# AS32x601 register map
File version: 1.0
CPU: RISC-V, little endian
Registers are 32-bit, read-write, reset 0x0 unless marked. A register's access mark holds for its fields unless they carry their own. Offsets are from the block's base; [hi:lo] are bit positions; lines under a group give offsets from that group; {n}, {i} and the like mark numbered series.

## CANFD0 — CAN FD Controller 0
Base 0x41010000
Same registers: CANFD1 0x41020000, CANFD2 0x42010000, CANFD3 0x42020000
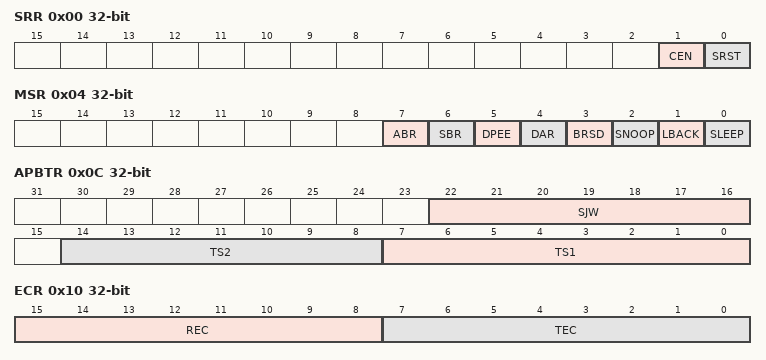
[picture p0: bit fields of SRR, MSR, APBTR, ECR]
0x00 SRR — Software Reset Register
  [1] CEN — CAN Enable
  [0] SRST — Reset
0x04 MSR — Mode Select Register
  [7] ABR — Auto Bus-Off Recovery Request
  [6] SBR — Start Bus-Off Recovery Request
  [5] DPEE — Disable Protocol Exception Event Detection/Generation
  [4] DAR — Disable Auto-Retransmission
  [3] BRSD — CAN FD Bit Rate Switch Disable Override
  [2] SNOOP — SNOOP Mode Select/Request
  [1] LBACK — Loopback Mode Select/Request
  [0] SLEEP — Sleep Mode Select/Request
0x08 APBRPR — Arbitration Phase (Nominal) Baud Rate Prescaler Register
  [7:0] BRP — BRP[7:0] bits (Arbitration Phase Baud Rate Prescaler)
0x0C APBTR — Arbitration Phase (Nominal) Bit Timing Register
  [22:16] SJW — SJW[6:0] bits (Synchronization Jump Width)
  [14:8] TS2 — TS2[6:0] bits (Time Segment 2)
  [7:0] TS1 — TS1[7:0] bits (Time Segment 1)
0x10 ECR ro — Error Count Register
  [15:8] REC — REC[7:0] bits (Receive Error Count)
  [7:0] TEC — TEC[7:0] bits (Transmit Error Count)
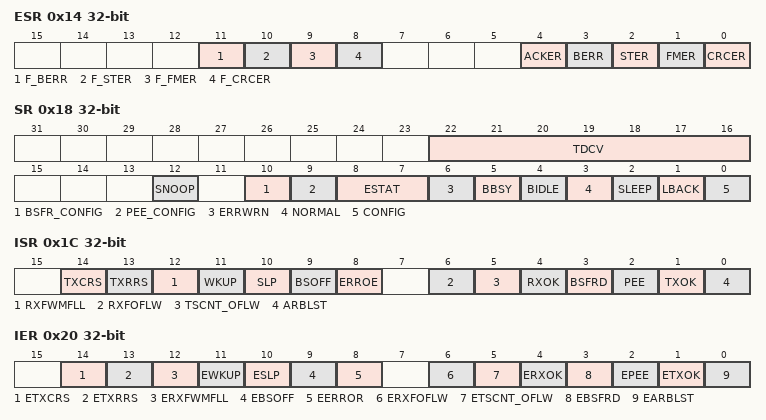
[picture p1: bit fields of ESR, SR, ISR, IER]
0x14 ESR — Error Status Register
  [11] F_BERR — Bit Error in CAN FD Data Phase
  [10] F_STER — Stuff Error in CAN FD Data Phase
  [9] F_FMER — Form Error in CAN FD Data Phase
  [8] F_CRCER — CRC Error in CAN FD Data Phase
  [4] ACKER — ACK Error
  [3] BERR — Bit Error
  [2] STER — Stuff Error
  [1] FMER — Form Error
  [0] CRCER — CRC Error
0x18 SR ro — Status Register
  [22:16] TDCV — TDCV[6:0] bits (Transmitter Delay Compensation Value)
  [12] SNOOP — Snoop Mode
  [10] BSFR_CONFIG — Bus-Off Recovery Mode Indicator
  [9] PEE_CONFIG — PEE Mode Indicator
  [8:7] ESTAT — ESTAT[1:0] bits (Error Status)
  [6] ERRWRN — Error Warning
  [5] BBSY — Indicates the CAN bus status
  [4] BIDLE — Bus Idle
  [3] NORMAL — Normal Mode
  [2] SLEEP — Sleep Mode
  [1] LBACK — Loopback Mode
  [0] CONFIG — Configuration Mode Indicator
0x1C ISR ro — Interrupt Status Register
  [14] TXCRS — TX Cancellation Request Served Interrupt
  [13] TXRRS — TX Buffer Ready Request Served Interrupt
  [12] RXFWMFLL — RX FIFO-0 Full Level Interrupt (sequential/FIFO mode)
  [11] WKUP — Wake-Up Interrupt
  [10] SLP — Sleep Interrupt
  [9] BSOFF — Bus-Off Interrupt
  [8] ERROE — Error Interrupt
  [6] RXFOFLW — RX FIFO-0 Overflow Interrupt
  [5] TSCNT_OFLW — Timestamp Counter Overflow Interrupt
  [4] RXOK — New Message Received Interrupt
  [3] BSFRD — Bus-Off Recovery Done Interrupt
  [2] PEE — Protocol Exception Event Interrupt
  [1] TXOK — Transmission Successful Interrupt
  [0] ARBLST — Arbitration Lost Interrupt
0x20 IER — Interrupt Enable Register
  [14] ETXCRS — TX Cancellation Request Served Interrupt Enable
  [13] ETXRRS — TX Buffer Ready Request Served Interrupt Enable
  [12] ERXFWMFLL — RX FIFO-0 Full Level Interrupt Enable (sequential/FIFO mode)
  [11] EWKUP — Wake-Up Interrupt Enable
  [10] ESLP — Sleep Interrupt Enable
  [9] EBSOFF — Bus-Off Interrupt Enable
  [8] EERROR — Error Interrupt Enable
  [6] ERXFOFLW — RX FIFO-0 Overflow Interrupt Enable
  [5] ETSCNT_OFLW — Timestamp Counter Overflow Interrupt Enable
  [4] ERXOK — New Message Received Interrupt Enable
  [3] EBSFRD — Bus-Off Recovery Done Interrupt Enable
  [2] EPEE — Protocol Exception Event Interrupt Enable
  [1] ETXOK — Transmission Successful Interrupt Enable
  [0] EARBLST — Arbitration Lost Interrupt Enable
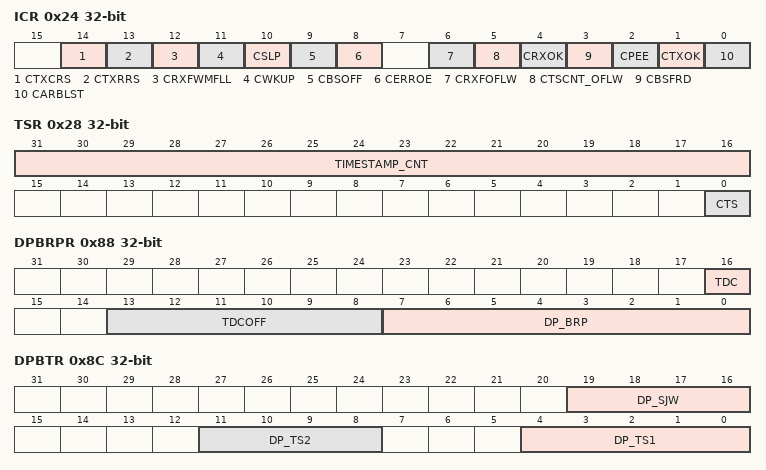
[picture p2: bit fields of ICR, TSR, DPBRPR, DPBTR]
0x24 ICR wo — Interrupt Clear Register
  [14] CTXCRS — Clears TX Cancellation Request Served Interrupt
  [13] CTXRRS — Clears TX Buffer Ready Request Served Interrupt
  [12] CRXFWMFLL — Clears RX FIFO-0 Full Level Interrupt(sequential/FIFO mode)
  [11] CWKUP — Clears Wake-Up interrupt
  [10] CSLP — Clears Sleep interrupt
  [9] CBSOFF — Clears Bus-Off interrupt
  [8] CERROE — Clears Error interrupt
  [6] CRXFOFLW — Clears RX FIFO-0 Overflow interrupt
  [5] CTSCNT_OFLW — Clears Timestamp Counter Overflow Interrupt
  [4] CRXOK — Clears New Message Received interrupt
  [3] CBSFRD — Clears Bus-Off Recovery Done interrupt
  [2] CPEE — Clears Protocol Exception Event interrupt
  [1] CTXOK — Clears Transmission Successful interrupt
  [0] CARBLST — Clears Arbitration Lost interrupt
0x28 TSR — Timestamp Register
  [31:16] TIMESTAMP_CNT — TIMESTAMP_CNT[15:0] bits (Timestamp Counter Value)
  [0] CTS — Clear Timestamp Counter
0x88 DPBRPR — Data Phase Baud Rate Prescaler Register
  [16] TDC — Transmitter Delay Compensation (TDC) Enable
  [13:8] TDCOFF — TDCOFF[5:0] bits (Transmitter Delay Compensation Offset)
  [7:0] DP_BRP — DP_BRP[7:0] bits (Data Phase Baud Rate Prescaler)
0x8C DPBTR — Data Phase Bit Timing Register
  [19:16] DP_SJW — DP_SJW[3:0] bits (Data Phase Synchronization Jump Width)
  [11:8] DP_TS2 — DP_TS2[3:0] bits (Data Phase Time Segment 2)
  [4:0] DP_TS1 — DP_TS1[4:0] bits (Data Phase Time Segment 1)
0x90 TRR — TX Buffer Ready Request Register
  [31:0] RR — RR[31:0] bits (TX Buffer Ready Request)
0x94 ERRS — Interrupt Enable TX Buffer Ready Request Served/Cleared
  [31:0] ERRS — ERRS[31:0] bits (TX Buffer Ready Req Served/Cleared Interrupt Enable)
0x98 TCR — TX Buffer Cancel Request
  [31:0] CR — CR[31:0] bits (TX Buffer Cancel Request)
0x9C ECRS — Interrupt Enable TX Buffer Cancellation Served/Cleared
  [31:0] ECRS — ECRS[31:0] bits (TX Buffer Transmission Served/Cleared Interrupt Enable)
0xE0 AFR — Acceptance Filter (Control) Register
  [31:0] UAF — UAF[31:0] bits (Use Acceptance Filter Mask Pair)
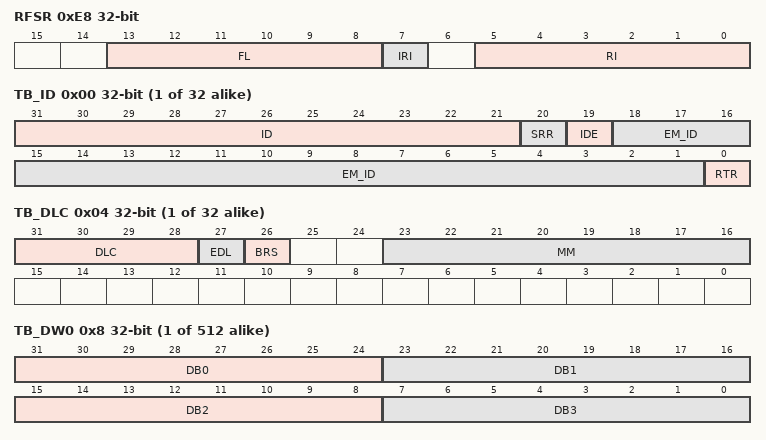
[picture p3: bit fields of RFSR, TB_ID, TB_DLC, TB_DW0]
0xE8 RFSR — RX FIFO Status Register
  [13:8] FL — FL[5:0] bits (RX FIFO Fill Level 0 to 64)
  [7] IRI — RX FIFO Increment Read Index by 1
  [5:0] RI — RI[5:0] bits (RX FIFO Read Index 0 to 63)
{0x100+0x48*i} TxMessage[{i}] (i=0..31) group — CAN FD TX Message Space Register Descriptions (32 pairs)
  0x00 TB_ID — TX Buffer ID Register
    [31:21] ID — ID[28:18] bits (Standard Message ID)
    [20] SRR — Substitute Remote Transmission Request
    [19] IDE — Identifier Extension
    [18:1] EM_ID — ID[17:0] bits (Extended Message ID)
    [0] RTR — Remote Transmission Request
  0x04 TB_DLC — TX Buffer DLC Register
    [31:28] DLC — DLC[3:0] bits (Data Length Code)
    [27] EDL — Extended Data Length/FD Frame Format
    [26] BRS — Bit Rate Switch
    [23:16] MM — MM[7:0] bits (Written by CPU during TX Buffer configuration)
  {0x8+4j} TB_DW{j} (j=0..15) — TX Buffer Data Word {j} Register
    [31-8n:24-8n] DB{n} (n=0..3) — Data bytes[7:0] bits {n} (Data Byte)
{0xA00+8i} RxFiltering[{i}] (i=0..31) group — Acceptance Filter Registers (32 pairs)
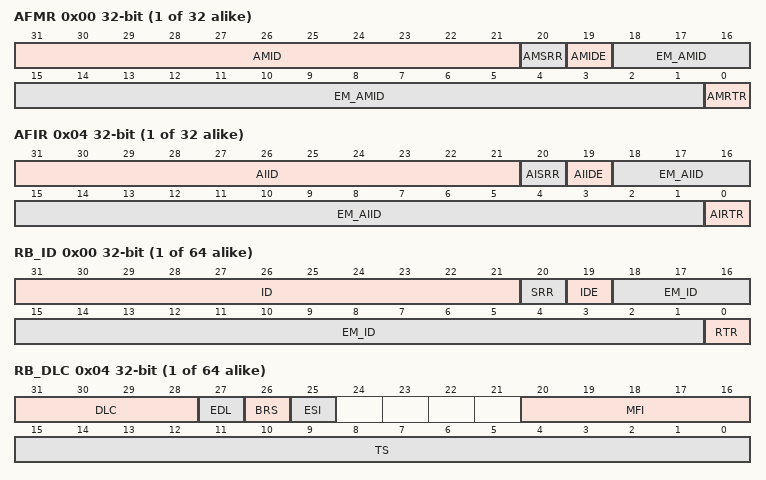
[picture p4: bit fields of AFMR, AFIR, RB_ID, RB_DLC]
  0x00 AFMR — Acceptance Filter Mask Register
    [31:21] AMID — Standard Message ID Mask
    [20] AMSRR — Substitute Remote Transmission Request Mask
    [19] AMIDE — Identifier Extension Mask
    [18:1] EM_AMID — Extended Message ID Mask
    [0] AMRTR — Remote Transmission Request Mask
  0x04 AFIR — Acceptance Filter ID Register
    [31:21] AIID — Standard Message ID
    [20] AISRR — Substitute Remote Transmission Request
    [19] AIIDE — Identifier Extension
    [18:1] EM_AIID — Extended Message ID
    [0] AIRTR — Remote Transmission Request
{0x2100+0x48*i} RxMessage[{i}] (i=0..63) group — CAN FD RX Message Space (Sequential/FIFO Buffers-RX FIFO) Register Descriptions
  0x00 RB_ID ro
    [31:21] ID — Standard Message ID
    [20] SRR — Substitute Remote Transmission Request
    [19] IDE — Identifier Extension
    [18:1] EM_ID — Extended Message ID
    [0] RTR — Remote Transmission Request
  0x04 RB_DLC ro
    [31:28] DLC — Data Length Code
    [27] EDL — Extended Data Length/FD Frame Format
    [26] BRS — Bit Rate Switch
    [25] ESI — Error State Indicator
    [20:16] MFI — Matched Filter Index
    [15:0] TS — Timestamp
  0x08 RB_DW0 ro
    [31:0] DB — Data Bytes
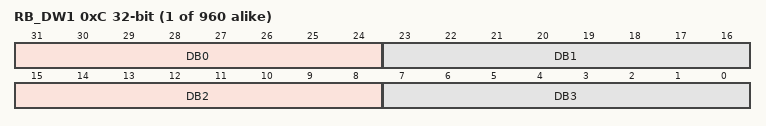
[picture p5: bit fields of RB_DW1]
  {0x8+4j} RB_DW{j} ro (j=1..15)
    [31-8n:24-8n] DB{n} (n=0..3) — Data bytes[7:0] bits {n} (Data Byte)
